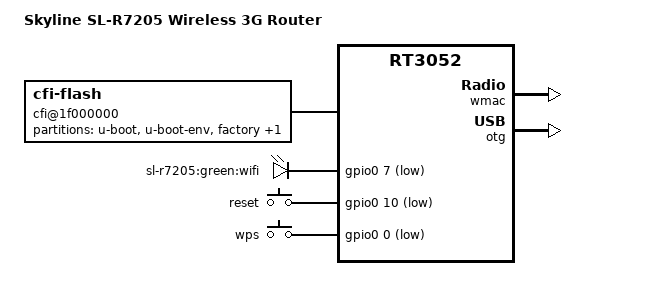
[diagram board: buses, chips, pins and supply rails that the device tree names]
/dts-v1/;

#include "rt3050.dtsi"

#include <dt-bindings/gpio/gpio.h>
#include <dt-bindings/input/input.h>

/ {
	compatible = "skyline,sl-r7205", "ralink,rt3052-soc";
	model = "Skyline SL-R7205 Wireless 3G Router";

	aliases {
		led-status = &led_wifi;
	};

	cfi@1f000000 {
		compatible = "cfi-flash";
		reg = <0x1f000000 0x800000>;
		bank-width = <2>;
		device-width = <2>;

		partitions {
			compatible = "fixed-partitions";
			#address-cells = <1>;
			#size-cells = <1>;

			partition@0 {
				label = "u-boot";
				reg = <0x0 0x30000>;
				read-only;
			};

			partition@30000 {
				label = "u-boot-env";
				reg = <0x30000 0x10000>;
				read-only;
			};

			factory: partition@40000 {
				label = "factory";
				reg = <0x40000 0x10000>;
				read-only;
			};

			partition@50000 {
				label = "firmware";
				reg = <0x50000 0x3b0000>;
			};
		};
	};

	gpio-leds {
		compatible = "gpio-leds";

		led_wifi: wifi {
			label = "sl-r7205:green:wifi";
			gpios = <&gpio0 7 GPIO_ACTIVE_LOW>;
		};
	};

	gpio-keys-polled {
		compatible = "gpio-keys-polled";
		poll-interval = <20>;

		reset {
			label = "reset";
			gpios = <&gpio0 10 GPIO_ACTIVE_LOW>;
			linux,code = <KEY_RESTART>;
		};

		wps {
			label = "wps";
			gpios = <&gpio0 0 GPIO_ACTIVE_LOW>;
			linux,code = <KEY_WPS_BUTTON>;
		};
	};
};

&pinctrl {
	state_default: pinctrl0 {
		gpio {
			ralink,group = "spi", "i2c", "jtag", "rgmii", "mdio", "uartf";
			ralink,function = "gpio";
		};
	};
};

&ethernet {
	mtd-mac-address = <&factory 0x4>;
};

&esw {
	mediatek,portmap = <0x3e>;
};

&wmac {
	ralink,mtd-eeprom = <&factory 0>;
};

&otg {
	status = "okay";
};
